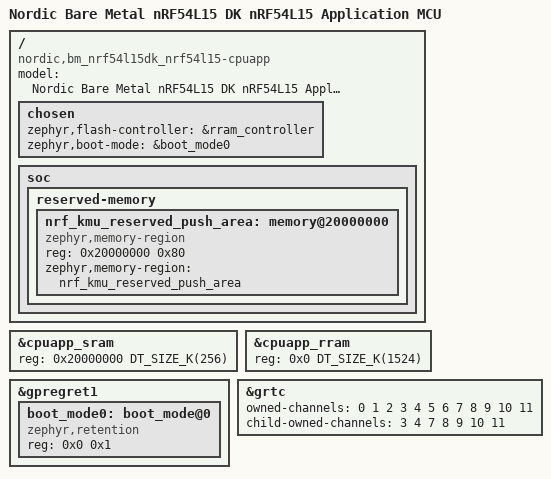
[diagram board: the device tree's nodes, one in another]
/*
 * Copyright (c) 2025 Nordic Semiconductor ASA
 *
 * SPDX-License-Identifier: LicenseRef-Nordic-5-Clause
 */

#include "bm_nrf54l15dk_nrf54l051015_peripherals.dtsi"

/ {
	compatible = "nordic,bm_nrf54l15dk_nrf54l15-cpuapp";
	model = "Nordic Bare Metal nRF54L15 DK nRF54L15 Application MCU";

	chosen {
		zephyr,flash-controller = &rram_controller;
		zephyr,boot-mode = &boot_mode0;
	};

	soc {
		reserved-memory {
			#address-cells = <1>;
			#size-cells = <1>;
			ranges;

			 nrf_kmu_reserved_push_area: memory@20000000 {
				reg = <0x20000000 0x80>;
				compatible = "zephyr,memory-region", "mmio-sram";
				zephyr,memory-region = "nrf_kmu_reserved_push_area";
				status = "okay";
			 };
		};
	};
};

/* Override NCS default to use entire SRAM for application CPU. */
&cpuapp_sram {
	reg = <0x20000000 DT_SIZE_K(256)>;
	ranges = <0x0 0x20000000 DT_SIZE_K(256)>;
};

/* Override NCS default to use entire RRAM for application CPU. */
&cpuapp_rram {
	reg = <0x0 DT_SIZE_K(1524)>;
};

&gpregret1 {
	status = "okay";

	boot_mode0: boot_mode@0 {
		compatible = "zephyr,retention";
		status = "okay";
		reg = <0x0 0x1>;
	};
};

&grtc {
	owned-channels = <0 1 2 3 4 5 6 7 8 9 10 11>;
	/* Channels 7-11 reserved for Zero Latency IRQs, 3-4 for FLPR */
	child-owned-channels = <3 4 7 8 9 10 11>;
	status = "okay";
};
